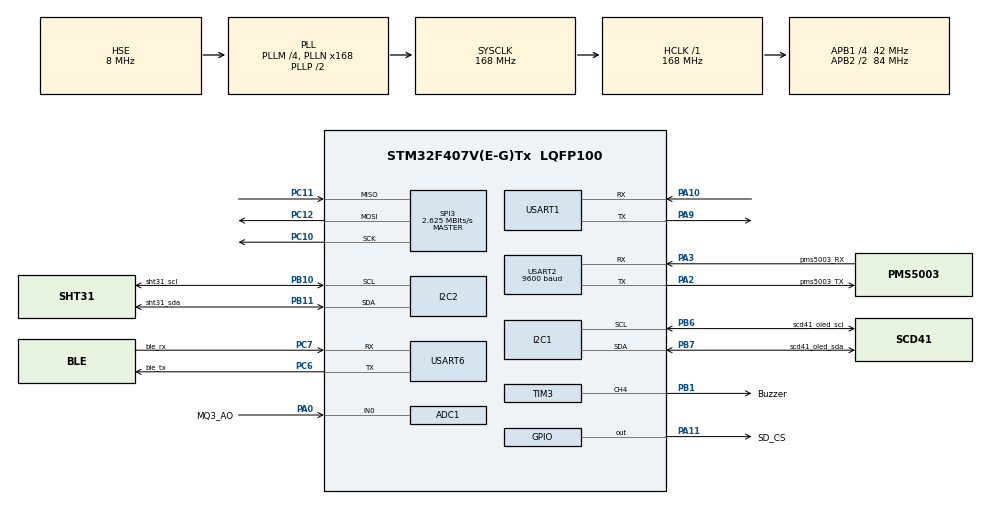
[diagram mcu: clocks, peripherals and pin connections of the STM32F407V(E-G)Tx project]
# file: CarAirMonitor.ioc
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ADC1.Channel-0\#ChannelRegularConversion=ADC_CHANNEL_0
ADC1.NbrOfConversionFlag=1
ADC1.Rank-0\#ChannelRegularConversion=1
ADC1.SamplingTime-0\#ChannelRegularConversion=ADC_SAMPLETIME_3CYCLES
ADC1.master=1
Mcu.Family=STM32F4
Mcu.Name=STM32F407V(E-G)Tx
Mcu.Package=LQFP100
NVIC.PriorityGroup=NVIC_PRIORITYGROUP_4
NVIC.USART2_IRQn=true\:0\:0\:false\:false\:true\:true\:true\:true
PA0-WKUP.GPIO_Label=MQ3_AO
PA0-WKUP.Signal=ADCx_IN0
PA10.Mode=Asynchronous
PA10.Signal=USART1_RX
PA11.GPIO_Label=SD_CS
PA11.GPIO_PuPd=GPIO_PULLUP
PA11.GPIO_Speed=GPIO_SPEED_FREQ_HIGH
PA11.PinState=GPIO_PIN_SET
PA11.Signal=GPIO_Output
PA13.Mode=Serial_Wire
PA13.Signal=SYS_JTMS-SWDIO
PA14.Mode=Serial_Wire
PA14.Signal=SYS_JTCK-SWCLK
PA2.GPIO_Label=pms5003_TX
PA2.Mode=Asynchronous
PA2.Signal=USART2_TX
PA3.GPIO_Label=pms5003_RX
PA3.Mode=Asynchronous
PA3.Signal=USART2_RX
PA9.Mode=Asynchronous
PA9.Signal=USART1_TX
PB1.GPIO_Label=Buzzer
PB1.Signal=S_TIM3_CH4
PB10.GPIO_Label=sht31_scl
PB10.GPIO_Pu=GPIO_PULLUP
PB10.Mode=I2C
PB10.Signal=I2C2_SCL
PB11.GPIO_Label=sht31_sda
PB11.GPIO_Pu=GPIO_PULLUP
PB11.Mode=I2C
PB11.Signal=I2C2_SDA
PB6.GPIO_Label=scd41_oled_scl
PB6.GPIO_Pu=GPIO_PULLUP
PB6.Mode=I2C
PB6.Signal=I2C1_SCL
PB7.GPIO_Label=scd41_oled_sda
PB7.GPIO_Pu=GPIO_PULLUP
PB7.Mode=I2C
PB7.Signal=I2C1_SDA
PC10.Mode=Full_Duplex_Master
PC10.Signal=SPI3_SCK
PC11.GPIO_PuPd=GPIO_PULLUP
PC11.Mode=Full_Duplex_Master
PC11.Signal=SPI3_MISO
PC12.Mode=Full_Duplex_Master
PC12.Signal=SPI3_MOSI
PC6.GPIO_Label=ble_tx
PC6.Mode=Asynchronous
PC6.Signal=USART6_TX
PC7.GPIO_Label=ble_rx
PC7.Mode=Asynchronous
PC7.Signal=USART6_RX
PH0-OSC_IN.Mode=HSE-External-Oscillator
PH0-OSC_IN.Signal=RCC_OSC_IN
PH1-OSC_OUT.Mode=HSE-External-Oscillator
PH1-OSC_OUT.Signal=RCC_OSC_OUT
ProjectManager.HeapSize=0x200
ProjectManager.StackSize=0x400
ProjectManager.TargetToolchain=STM32CubeIDE
RCC.48MHZClocksFreq_Value=84000000
RCC.AHBFreq_Value=168000000
RCC.APB1CLKDivider=RCC_HCLK_DIV4
RCC.APB1Freq_Value=42000000
RCC.APB1TimFreq_Value=84000000
RCC.APB2CLKDivider=RCC_HCLK_DIV2
RCC.APB2Freq_Value=84000000
RCC.APB2TimFreq_Value=168000000
RCC.CortexFreq_Value=168000000
RCC.HCLKFreq_Value=168000000
RCC.HSE_VALUE=8000000
RCC.HSI_VALUE=16000000
RCC.LSE_VALUE=32768
RCC.PLLM=4
RCC.PLLN=168
RCC.PLLSourceVirtual=RCC_PLLSOURCE_HSE
RCC.SYSCLKFreq_VALUE=168000000
RCC.SYSCLKSource=RCC_SYSCLKSOURCE_PLLCLK
RCC.VCOOutputFreq_Value=336000000
SH.ADCx_IN0.0=ADC1_IN0,IN0
SH.S_TIM3_CH4.0=TIM3_CH4,PWM Generation4 CH4
SPI3.BaudRatePrescaler=SPI_BAUDRATEPRESCALER_16
SPI3.CalculateBaudRate=2.625 MBits/s
SPI3.Direction=SPI_DIRECTION_2LINES
SPI3.Mode=SPI_MODE_MASTER
SPI3.VirtualType=VM_MASTER
TIM3.Channel-PWM\ Generation4\ CH4=TIM_CHANNEL_4
TIM3.Period=1000-1
TIM3.Prescaler=168-1
TIM3.Pulse-PWM\ Generation4\ CH4=50
USART1.VirtualMode=VM_ASYNC
USART2.BaudRate=9600
USART2.VirtualMode=VM_ASYNC
USART6.VirtualMode=VM_ASYNC
VP_FATFS_VS_Generic.Mode=User_defined
board=custom

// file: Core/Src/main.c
/* USER CODE BEGIN Header */
/**
  ******************************************************************************
  * @file           : main.c
  * @brief          : Main program body
  ******************************************************************************
  * @attention
  *
  * Copyright (c) 2026 STMicroelectronics.
  * All rights reserved.
  *
  * This software is licensed under terms that can be found in the LICENSE file
  * in the root directory of this software component.
  * If no LICENSE file comes with this software, it is provided AS-IS.
  *
  ******************************************************************************
  */
/* USER CODE END Header */
#include "main.h"
#include "adc.h"
#include "fatfs.h"
#include "i2c.h"
#include "spi.h"
#include "tim.h"
#include "usart.h"
#include "gpio.h"

/* USER CODE BEGIN Includes */
#include "sensor_manager.h"
#include <stdio.h>
/* USER CODE END Includes */

/* USER CODE BEGIN PV */
uint8_t UART2_RxData; // PMS5003串口接收数据变量
/* USER CODE END PV */

void SystemClock_Config(void);

int main(void)
{

  /* MCU Configuration--------------------------------------------------------*/

  /* Reset of all peripherals, Initializes the Flash interface and the Systick. */
  HAL_Init();

  /* Configure the system clock */
  SystemClock_Config();

  /* Initialize all configured peripherals */
  MX_GPIO_Init();
  MX_ADC1_Init();
  MX_I2C1_Init();
  MX_I2C2_Init();
  MX_SPI3_Init();
  MX_TIM3_Init();
  MX_USART1_UART_Init();
  MX_USART2_UART_Init();
  MX_USART6_UART_Init();
  MX_FATFS_Init();
  /* USER CODE BEGIN 2 */
  Sensor_Manager_Init();
  /* USER CODE END 2 */

  /* Infinite loop */
  /* USER CODE BEGIN WHILE */
  while (1)
  {
    Sensor_Manager_Collect_Alarm();
    HAL_Delay(COLLECT_INTERVAL_MS); // 统一采集间隔
    /* USER CODE END WHILE */

  }
}

void SystemClock_Config(void)
{
  RCC_OscInitTypeDef RCC_OscInitStruct = {0};
  RCC_ClkInitTypeDef RCC_ClkInitStruct = {0};

  /** Configure the main internal regulator output voltage
  */
  __HAL_RCC_PWR_CLK_ENABLE();
  __HAL_PWR_VOLTAGESCALING_CONFIG(PWR_REGULATOR_VOLTAGE_SCALE1);

  /** Initializes the RCC Oscillators according to the specified parameters
  * in the RCC_OscInitTypeDef structure.
  */
  RCC_OscInitStruct.OscillatorType = RCC_OSCILLATORTYPE_HSE;
  RCC_OscInitStruct.HSEState = RCC_HSE_ON;
  RCC_OscInitStruct.PLL.PLLState = RCC_PLL_ON;
  RCC_OscInitStruct.PLL.PLLSource = RCC_PLLSOURCE_HSE;
  RCC_OscInitStruct.PLL.PLLM = 4;
  RCC_OscInitStruct.PLL.PLLN = 168;
  RCC_OscInitStruct.PLL.PLLP = RCC_PLLP_DIV2;
  RCC_OscInitStruct.PLL.PLLQ = 4;
  if (HAL_RCC_OscConfig(&RCC_OscInitStruct) != HAL_OK)
  {
    Error_Handler();
  }

  /** Initializes the CPU, AHB and APB buses clocks
  */
  RCC_ClkInitStruct.ClockType = RCC_CLOCKTYPE_HCLK|RCC_CLOCKTYPE_SYSCLK
                              |RCC_CLOCKTYPE_PCLK1|RCC_CLOCKTYPE_PCLK2;
  RCC_ClkInitStruct.SYSCLKSource = RCC_SYSCLKSOURCE_PLLCLK;
  RCC_ClkInitStruct.AHBCLKDivider = RCC_SYSCLK_DIV1;
  RCC_ClkInitStruct.APB1CLKDivider = RCC_HCLK_DIV4;
  RCC_ClkInitStruct.APB2CLKDivider = RCC_HCLK_DIV2;

  if (HAL_RCC_ClockConfig(&RCC_ClkInitStruct, FLASH_LATENCY_5) != HAL_OK)
  {
    Error_Handler();
  }
}

void Error_Handler(void)
{
  __disable_irq();
  while (1)
  {
  }
}
